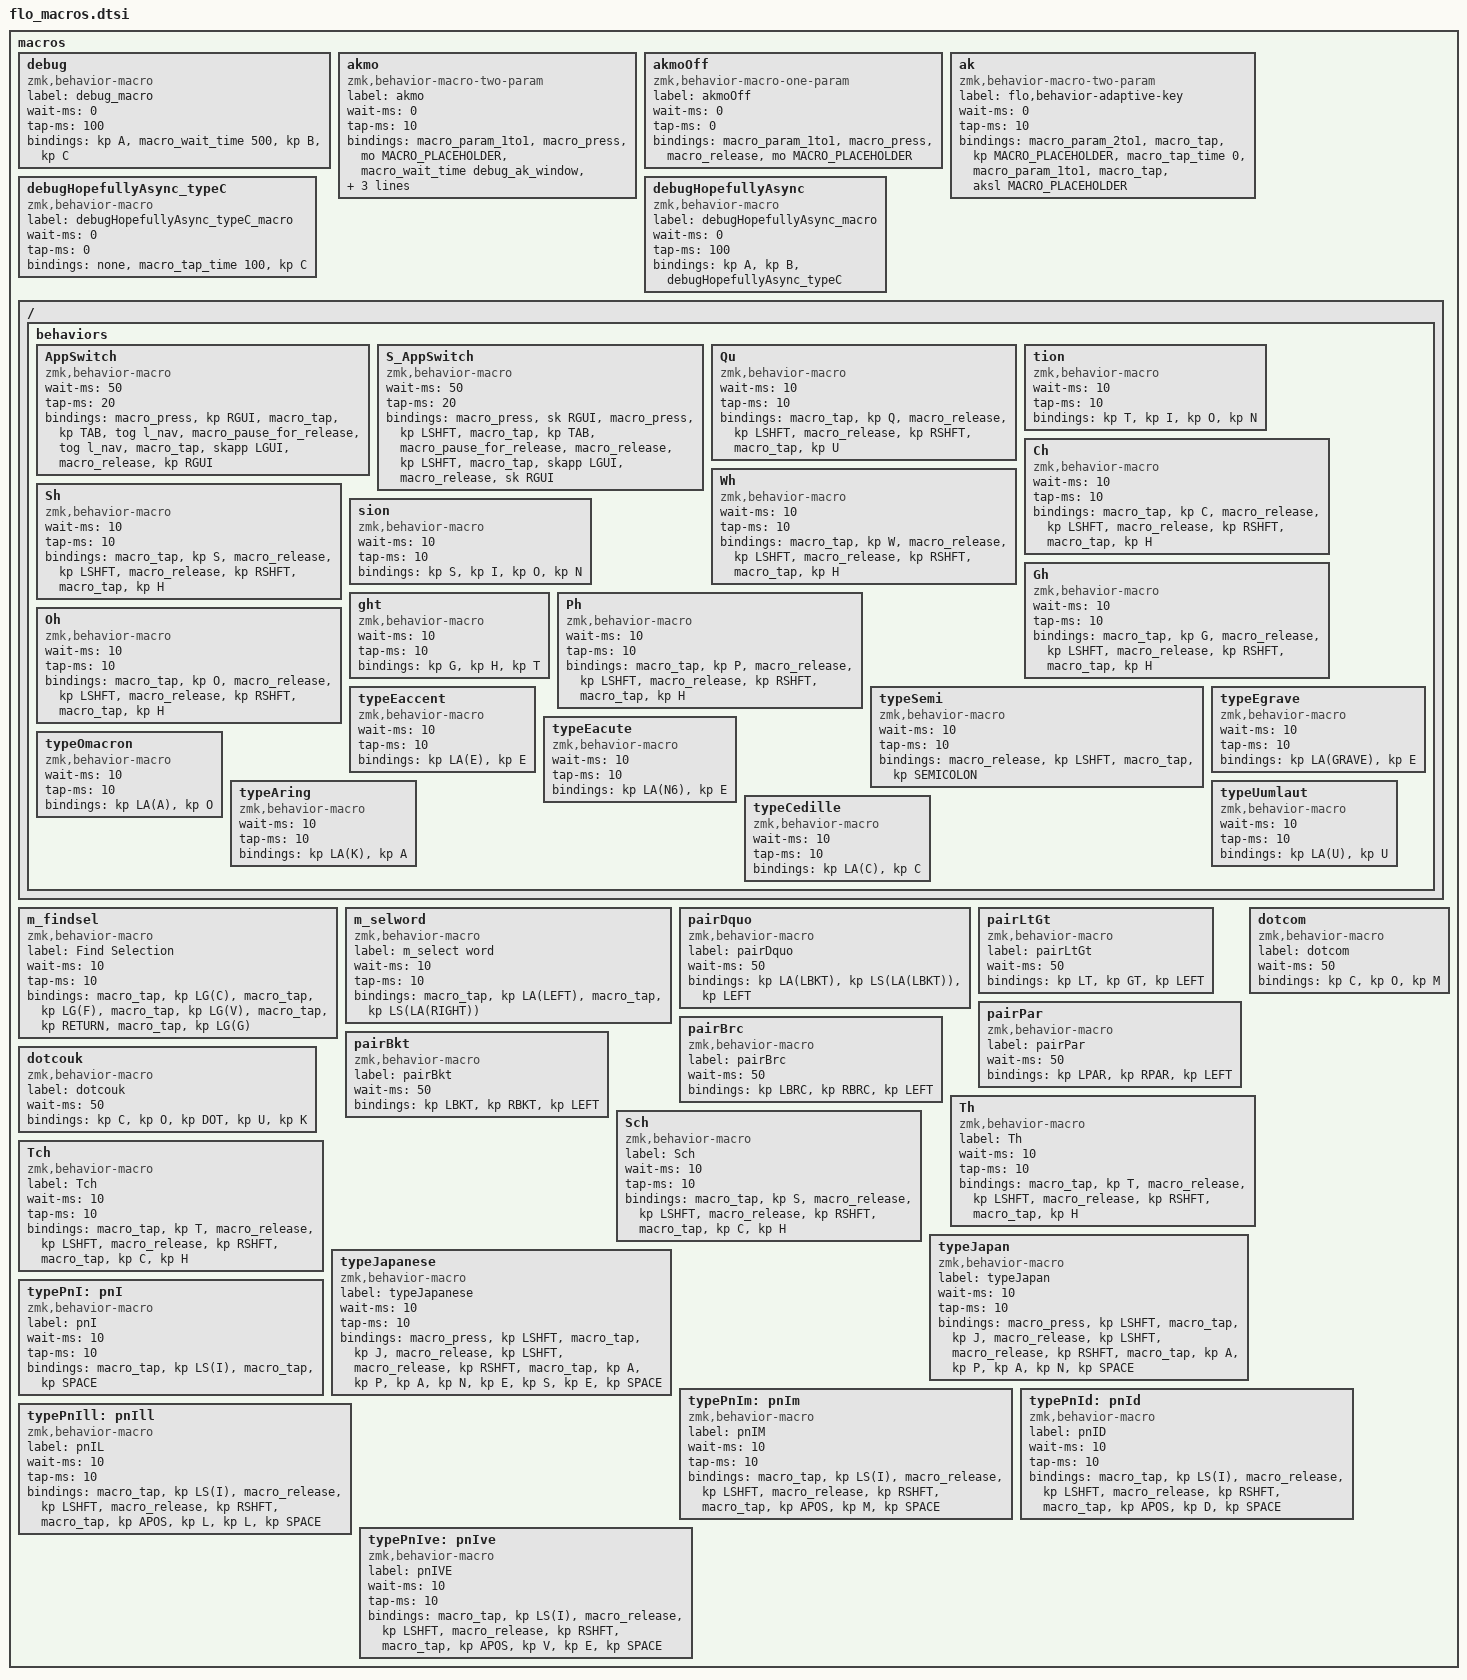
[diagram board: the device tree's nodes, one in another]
#define STRINGIFY(ARG) #ARG
#define REPLACE_CHAR_WITH_BIGRAM(BIGRAM_0, BIGRAM_1) \
        replace_char_with_bigram_##BIGRAM_0##BIGRAM_1: replace_char_with_bigram##BIGRAM_0##BIGRAM_1 { \
                label = STRINGIFY(flo-macro-replace-char-with-bigram-##BIGRAM_0##BIGRAM_1); \
                compatible = "zmk,behavior-macro"; \
                #binding-cells = <0>; \
                wait-ms = <0>; \
                tap-ms = <10>; \
                bindings = \
                        <&kp BACKSPACE>, \
\
                        <&kp BIGRAM_0>, \
\
                        <ak_##BIGRAM_1>; \
        };

macros {

        // Replace w/ Bigram for Vv only
        REPLACE_CHAR_WITH_BIGRAM(O, B)
        REPLACE_CHAR_WITH_BIGRAM(U, B)
        REPLACE_CHAR_WITH_BIGRAM(L, M)

        // Replace w/ Bigram for Vb
        REPLACE_CHAR_WITH_BIGRAM(S, B)
        REPLACE_CHAR_WITH_BIGRAM(I, F)
        REPLACE_CHAR_WITH_BIGRAM(L, G)
        REPLACE_CHAR_WITH_BIGRAM(B, J)
        REPLACE_CHAR_WITH_BIGRAM(D, J)
        REPLACE_CHAR_WITH_BIGRAM(N, J)
        REPLACE_CHAR_WITH_BIGRAM(L, K)
        REPLACE_CHAR_WITH_BIGRAM(N, K)
        REPLACE_CHAR_WITH_BIGRAM(B, M)
        REPLACE_CHAR_WITH_BIGRAM(L, N)
        REPLACE_CHAR_WITH_BIGRAM(N, M)
        REPLACE_CHAR_WITH_BIGRAM(P, M)

        debug: debug {
                label = "debug_macro";
                compatible = "zmk,behavior-macro";
                #binding-cells = <0>;
                wait-ms = <0>;
                tap-ms = <100>;
                bindings = 
                        <&kp A>,
                        <&macro_wait_time 500>,
                        <&kp B>,
                        <&kp C>;
        };

        // TODO: TRy with wait times, I think that's how I got it to work earlier. 
        // If can't figure out, reproduce the setup with 1000, 2000, 3000, 4000 delays to try and undersatnd again how it works.
        // YEEEEEEEEEEES THIS SEEMS TO WORK!!!! (somewhat, need to investigate more tomorrow 😌)
        // mmmm maybe not actually. Need to double check with 1000, 2000, etc..
#define debug_ak_window (my_ak_window / 2) // This is because the ak_window is doubled in the macro. I may be able to fix this later.
        akmo: akmo {
                label = "akmo";
                compatible = "zmk,behavior-macro-two-param";
                #binding-cells = <2>;
                wait-ms = <0>;
                tap-ms = <10>; // Was 0, but trying 10ms since I add a &kp in the mix
                bindings = 
                        <&macro_param_1to1>,
                        <&macro_press &mo MACRO_PLACEHOLDER>,

                        <&macro_wait_time debug_ak_window>,
                        <&macro_param_2to1>,
                        // <&macro_tap &kp MACRO_PLACEHOLDER>, // This one will pause 'ak_window' after invoked (before invoking &akmoOff)
                        <&macro_press &bk MACRO_PLACEHOLDER>, // This one will pause 'ak_window' after invoked (before invoking &akmoOff)

                        <&macro_param_1to1>,
                        <&macro_press &akmoOff MACRO_PLACEHOLDER>;
        };
        akmoOff: akmoOff {
                label = "akmoOff";
                compatible = "zmk,behavior-macro-one-param";
                #binding-cells = <1>;
                wait-ms = <0>; // Wait will only delay the _next_ action, but this macro only has one action, so it's useless here (and it would delay the 1st action of the next macro => Confusing!)
                tap-ms = <0>; // Tap is not used when just realeasing (&macro_release)
                bindings = 
                        <&macro_param_1to1>,
                        <&macro_press &macro_release &mo MACRO_PLACEHOLDER>;
        };

        ak: ak {
                label = "flo,behavior-adaptive-key";
                compatible = "zmk,behavior-macro-two-param";
                #binding-cells = <2>;
                wait-ms = <0>;
                tap-ms = <10>;
                bindings =
                        <&macro_param_2to1>,
                        <&macro_tap &kp MACRO_PLACEHOLDER>,

                        <&macro_tap_time 0>,

                        <&macro_param_1to1>,
                        <&macro_tap &aksl MACRO_PLACEHOLDER>;
        };


/*

THIS is the version from the drawings on reMarkable!

        akmo: akmo {
                label = "akmo";
                compatible = "zmk,behavior-macro";
                #binding-cells = <0>;
                wait-ms = <1000>;
                tap-ms = <0>; // Unused because we are just pressing (&macro_press, &akmoOff)
                bindings = 
                        <&macro_press &mo 10>,
                        <&akmoOff>;
        };
        akmoOff: akmoOff {
                label = "akmoOff";
                compatible = "zmk,behavior-macro";
                #binding-cells = <0>;
                wait-ms = <0>; // Wait will only delay the _next_ action, but this macro only has one action, so it's useless here (and it would delay the 1st action of the next macro => Confusing!)
                tap-ms = <0>; // Tap is not used when just realeasing (&macro_release)
                bindings = 
                        <&macro_release &mo 10>;
        };

*/






        debugHopefullyAsync_typeC: debugHopefullyAsync_typeC {
                label = "debugHopefullyAsync_typeC_macro";
                compatible = "zmk,behavior-macro";
                #binding-cells = <0>;
                wait-ms = <0>;
                tap-ms = <0>;
                bindings = 
                <&none>,
                <&macro_tap_time 100>,
                <&kp C>;
        };
        debugHopefullyAsync: debugHopefullyAsync {
                label = "debugHopefullyAsync_macro";
                compatible = "zmk,behavior-macro";
                #binding-cells = <0>;
                wait-ms = <0>;
                tap-ms = <100>;
                bindings = 
                        <&kp A>,
                        <&kp B>,
                        <&debugHopefullyAsync_typeC>;
        };


        ZMK_MACRO(AppSwitch,
                wait-ms = <50>;
                tap-ms = <20>;
                bindings =
                        <&macro_press &kp RGUI>    // leave GUI down to keep menu up
                        , <&macro_tap &kp TAB>       // (use press for repeat)
                        , <&tog l_nav>               // to navigate the app menu
                        , <&macro_pause_for_release> // hold to keep menu up or for repeat ...
                        , <&tog l_nav>               // done navigating
                        , <&macro_tap &skapp LGUI>   // release other GUI after a timeout
                        , <&macro_release &kp RGUI>  // release the previous hold
                        ;
        )
        ZMK_MACRO(S_AppSwitch,
                wait-ms = <50>;
                tap-ms = <20>;
                bindings =
                        <&macro_press &sk RGUI> // leave GUI down to keep menu up
                        , <&macro_press &kp LSHFT> //
                        , <&macro_tap &kp TAB> // just tap for no repeat
                        , <&macro_pause_for_release> // hold for repeat ...
                        , <&macro_release &kp LSHFT> //
                        , <&macro_tap &skapp LGUI> // release other GUI after a timeout
                        , <&macro_release &sk RGUI> // now release the previous hold
                        ;
        )



        m_findsel: m_findsel {
                label = "Find Selection";
                compatible = "zmk,behavior-macro";
                #binding-cells = <0>;
                wait-ms = <10>;
                tap-ms = <10>;
                bindings = <&macro_tap &kp LG(C)>
                        , <&macro_tap &kp LG(F)>
                        , <&macro_tap &kp LG(V)>
                        , <&macro_tap &kp RETURN>
                        , <&macro_tap &kp LG(G)>;
        };

        m_selword: m_selword {
                label = "m_select word";
                compatible = "zmk,behavior-macro";
                #binding-cells = <0>;
                wait-ms = <10>;
                tap-ms = <10>;
                bindings = <&macro_tap &kp LA(LEFT)>
                        , <&macro_tap &kp LS(LA(RIGHT))>;
        };


        ZMK_MACRO(Qu,
                wait-ms = <10>;
                tap-ms = <10>;
                bindings = <&macro_tap &kp Q>
                        , <&macro_release &kp LSHFT>
                        , <&macro_release &kp RSHFT>
                        , <&macro_tap &kp U>
                        ;
        )

        pairDquo: pairDquo {
                label = "pairDquo";
                compatible = "zmk,behavior-macro";
                #binding-cells = <0>;
                wait-ms = <50>; // need to slow this down for some systems.
                bindings = <&kp LA(LBKT) &kp LS(LA(LBKT)) &kp LEFT>;
        };
        pairLtGt: pairLtGt {
                label = "pairLtGt";
                compatible = "zmk,behavior-macro";
                #binding-cells = <0>;
                wait-ms = <50>; // need to slow this down for some systems.
                bindings = <&kp LT &kp GT &kp LEFT>;
        };
        pairPar: pairPar {
                label = "pairPar";
                compatible = "zmk,behavior-macro";
                #binding-cells = <0>;
                wait-ms = <50>; // need to slow this down for some systems.
                bindings = <&kp LPAR &kp RPAR &kp LEFT>;
        };
        pairBrc: pairBrc {
                label = "pairBrc";
                compatible = "zmk,behavior-macro";
                #binding-cells = <0>;
                wait-ms = <50>; // need to slow this down for some systems.
                bindings = <&kp LBRC &kp RBRC &kp LEFT>;
        };
        pairBkt: pairBkt {
                label = "pairBkt";
                compatible = "zmk,behavior-macro";
                #binding-cells = <0>;
                wait-ms = <50>; // need to slow this down for some systems.
                bindings = <&kp LBKT &kp RBKT &kp LEFT>;
        };

        dotcom: dotcom {
                label = "dotcom";
                compatible = "zmk,behavior-macro";
                #binding-cells = <0>;
                wait-ms = <50>; // need to slow this down for some systems.
                bindings = <&kp C &kp O &kp M> ;
        };
        dotcouk: dotcouk {
                label = "dotcouk";
                compatible = "zmk,behavior-macro";
                #binding-cells = <0>;
                wait-ms = <50>; // need to slow this down for some systems.
                bindings = <&kp C &kp O &kp DOT &kp U &kp K>;
        };


// TODO: Rework all digraphs with a 2 param macro
        Th: Th {
                label = "Th";
                compatible = "zmk,behavior-macro";
                #binding-cells = <0>;
                wait-ms = <10>;
                tap-ms = <10>;
                bindings = <&macro_tap &kp T>
                , <&macro_release &kp LSHFT>
                , <&macro_release &kp RSHFT>
                , <&macro_tap &kp H>;
        };
        ZMK_MACRO(tion,
                wait-ms = <10>;
                tap-ms = <10>;
                bindings = <&kp T &kp I &kp O &kp N>;
        )
        ZMK_MACRO(Ch,
                wait-ms = <10>;
                tap-ms = <10>;
                bindings = <&macro_tap &kp C>
                        , <&macro_release &kp LSHFT>
                        , <&macro_release &kp RSHFT>
                        , <&macro_tap &kp H>;
        )
        ZMK_MACRO(Wh,
                wait-ms = <10>;
                tap-ms = <10>;
                bindings = <&macro_tap &kp W>
                        , <&macro_release &kp LSHFT>
                        , <&macro_release &kp RSHFT>
                        , <&macro_tap &kp H>;
        )
        ZMK_MACRO(Sh,
                wait-ms = <10>;
                tap-ms = <10>;
                bindings = <&macro_tap &kp S>
                        , <&macro_release &kp LSHFT>
                        , <&macro_release &kp RSHFT>
                        , <&macro_tap &kp H>
                        ;
                )
        ZMK_MACRO(sion,
                wait-ms = <10>;
                tap-ms = <10>;
                bindings = <&kp S &kp I &kp O &kp N>
                        ;
                )
        ZMK_MACRO(Gh,
                wait-ms = <10>;
                tap-ms = <10>;
                bindings = <&macro_tap &kp G>
                        , <&macro_release &kp LSHFT>
                        , <&macro_release &kp RSHFT>
                        , <&macro_tap &kp H>
                        ;
                )
        ZMK_MACRO(ght,
                wait-ms = <10>;
                tap-ms = <10>;
                bindings = <&kp G &kp H &kp T>
                        ;
                )
        ZMK_MACRO(Ph,
                wait-ms = <10>;
                tap-ms = <10>;
                bindings = <&macro_tap &kp P>
                        , <&macro_release &kp LSHFT>
                        , <&macro_release &kp RSHFT>
                        , <&macro_tap &kp H>
                        ;
                )
        ZMK_MACRO(Oh,
                wait-ms = <10>;
                tap-ms = <10>;
                bindings = <&macro_tap &kp O>
                        , <&macro_release &kp LSHFT>
                        , <&macro_release &kp RSHFT>
                        , <&macro_tap &kp H>
                        ;
                )


        Sch: Sch {
                label = "Sch";
                compatible = "zmk,behavior-macro";
                #binding-cells = <0>;
                wait-ms = <10>;
                tap-ms = <10>;
                bindings = <&macro_tap &kp S>
                        , <&macro_release &kp LSHFT>
                        , <&macro_release &kp RSHFT>
                        , <&macro_tap &kp C &kp H>
                        ;
        };
        Tch: Tch {
                label = "Tch";
                compatible = "zmk,behavior-macro";
                #binding-cells = <0>;
                wait-ms = <10>;
                tap-ms = <10>;
                bindings = <&macro_tap &kp T>
                        , <&macro_release &kp LSHFT>
                        , <&macro_release &kp RSHFT>
                        , <&macro_tap &kp C &kp H>
                        ;
        };

        ZMK_MACRO(typeSemi,
                wait-ms = <10>;
                tap-ms = <10>;
                bindings = <&macro_release &kp LSHFT>
                        , <&macro_tap &kp SEMICOLON>
                        ;
        )
        ZMK_MACRO(typeEaccent,
                wait-ms = <10>;
                tap-ms = <10>;
                bindings = <&kp LA(E) &kp E>
                        ;
        )
        ZMK_MACRO(typeEgrave,
                wait-ms = <10>;
                tap-ms = <10>;
                bindings = <&kp LA(GRAVE) &kp E>
                        ;
        )
        ZMK_MACRO(typeEacute,
                wait-ms = <10>;
                tap-ms = <10>;
                bindings = <&kp LA(N6) &kp E>
                        ;
        )
        ZMK_MACRO(typeOmacron,
                wait-ms = <10>;
                tap-ms = <10>;
                bindings = <&kp LA(A) &kp O>
                        ;
        )
        ZMK_MACRO(typeAring,
                wait-ms = <10>;
                tap-ms = <10>;
                bindings = <&kp LA(K) &kp A>
                        ;
        )
        ZMK_MACRO(typeUumlaut,
                wait-ms = <10>;
                tap-ms = <10>;
                bindings = <&kp LA(U) &kp U>
                        ;
        )
        ZMK_MACRO(typeCedille,
                wait-ms = <10>;
                tap-ms = <10>;
                bindings = <&kp LA(C) &kp C>
                        ;
        )
        typeJapan: typeJapan {
                label = "typeJapan";
                compatible = "zmk,behavior-macro";
                #binding-cells = <0>;
                wait-ms = <10>;
                tap-ms = <10>;
                bindings = <&macro_press &kp LSHFT>
                        , <&macro_tap &kp J>
                        , <&macro_release &kp LSHFT>
                        , <&macro_release &kp RSHFT>
                        , <&macro_tap &kp A &kp P &kp A &kp N &kp SPACE>
                        ;
        };
        typeJapanese: typeJapanese {
                label = "typeJapanese";
                compatible = "zmk,behavior-macro";
                #binding-cells = <0>;
                wait-ms = <10>;
                tap-ms = <10>;
                bindings = <&macro_press &kp LSHFT>
                        , <&macro_tap &kp J>
                        , <&macro_release &kp LSHFT>
                        , <&macro_release &kp RSHFT>
                        , <&macro_tap &kp A &kp P &kp A &kp N &kp E &kp S &kp E &kp SPACE>
                        ;
        };





        // I
        typePnI: pnI {
                label = "pnI";
                compatible = "zmk,behavior-macro";
                #binding-cells = <0>;
                wait-ms = <10>;
                tap-ms = <10>;
                bindings = <&macro_tap &kp LS(I)>
                        , <&macro_tap &kp SPACE>
                        ;
        };
        typePnIm: pnIm {
                label = "pnIM";
                compatible = "zmk,behavior-macro";
                #binding-cells = <0>;
                wait-ms = <10>;
                tap-ms = <10>;
                bindings = <&macro_tap &kp LS(I)>
                        , <&macro_release &kp LSHFT>
                        , <&macro_release &kp RSHFT>
                        , <&macro_tap &kp APOS &kp M &kp SPACE>
                        ;
        };
        typePnId: pnId {
                label = "pnID";
                compatible = "zmk,behavior-macro";
                #binding-cells = <0>;
                wait-ms = <10>;
                tap-ms = <10>;
                bindings = <&macro_tap &kp LS(I)>
                        , <&macro_release &kp LSHFT>
                        , <&macro_release &kp RSHFT>
                        , <&macro_tap &kp APOS &kp D &kp SPACE>
                        ;
        };
        typePnIll: pnIll {
                label = "pnIL";
                compatible = "zmk,behavior-macro";
                #binding-cells = <0>;
                wait-ms = <10>;
                tap-ms = <10>;
                bindings = <&macro_tap &kp LS(I)>
                        , <&macro_release &kp LSHFT>
                        , <&macro_release &kp RSHFT>
                        , <&macro_tap &kp APOS &kp L &kp L &kp SPACE>
                        ;
        };
        typePnIve: pnIve {
                label = "pnIVE";
                compatible = "zmk,behavior-macro";
                #binding-cells = <0>;
                wait-ms = <10>;
                tap-ms = <10>;
                bindings = <&macro_tap &kp LS(I)>
                        , <&macro_release &kp LSHFT>
                        , <&macro_release &kp RSHFT>
                        , <&macro_tap &kp APOS &kp V &kp E &kp SPACE>
                        ;
        };

        // // YOU
        // typePnYoure: pnYoure {
        //         label = "pnYoure";
        //         compatible = "zmk,behavior-macro";
        //         #binding-cells = <0>;
        //         wait-ms = <10>;
        //         tap-ms = <10>;
        //         bindings = <&macro_tap &kp Y>
        //                 , <&macro_release &kp LSHFT>
        //                 , <&macro_release &kp RSHFT>
        //                 , <&macro_tap &kp O &kp U &kp APOS &kp R &kp E &kp SPACE>
        //                 ;
        // };
        // typePnYoud: pnYoud {
        //         label = "pnYou'd";
        //         compatible = "zmk,behavior-macro";
        //         #binding-cells = <0>;
        //         wait-ms = <10>;
        //         tap-ms = <10>;
        //         bindings = <&macro_tap &kp Y>
        //                 , <&macro_release &kp LSHFT>
        //                 , <&macro_release &kp RSHFT>
        //                 , <&macro_tap &kp O &kp U &kp APOS &kp D &kp SPACE>
        //                 ;
        // };
        // typePnYoull: pnYoull {
        //         label = "pnYou'll";
        //         compatible = "zmk,behavior-macro";
        //         #binding-cells = <0>;
        //         wait-ms = <10>;
        //         tap-ms = <10>;
        //         bindings = <&macro_tap &kp Y>
        //                 , <&macro_release &kp LSHFT>
        //                 , <&macro_release &kp RSHFT>
        //                 , <&macro_tap &kp O &kp U &kp APOS &kp L &kp L &kp SPACE>
        //                 ;
        //         };
        // typePnYouve: pnYouve {
        // label = "pnYou've";
        //         compatible = "zmk,behavior-macro";
        //         #binding-cells = <0>;
        //         wait-ms = <10>;
        //         tap-ms = <10>;
        //         bindings = <&macro_tap &kp Y>
        //                 , <&macro_release &kp LSHFT>
        //                 , <&macro_release &kp RSHFT>
        //                 , <&macro_tap &kp O &kp U &kp APOS &kp V &kp E &kp SPACE>
        //                 ;
        //         };

        // // WE
        // typePnWere: pnWere {
        //         label = "pnWere";
        //         compatible = "zmk,behavior-macro";
        //         #binding-cells = <0>;
        //         wait-ms = <10>;
        //         tap-ms = <10>;
        //         bindings = <&macro_tap &kp W>
        //                 , <&macro_release &kp LSHFT>
        //                 , <&macro_release &kp RSHFT>
        //                 , <&macro_tap &kp E &kp APOS &kp R &kp E &kp SPACE>
        //                 ;
        // };
        // typePnWed: pnWed {
        //         label = "pnWe'd";
        //         compatible = "zmk,behavior-macro";
        //         #binding-cells = <0>;
        //         wait-ms = <10>;
        //         tap-ms = <10>;
        //         bindings = <&macro_tap &kp W>
        //                 , <&macro_release &kp LSHFT>
        //                 , <&macro_release &kp RSHFT>
        //                 , <&macro_tap &kp E &kp APOS &kp D &kp SPACE>
        //                 ;
        // };
        // typePnWell: pnWell {
        //         label = "pnWe'll";
        //         compatible = "zmk,behavior-macro";
        //         #binding-cells = <0>;
        //         wait-ms = <10>;
        //         tap-ms = <10>;
        //         bindings = <&macro_tap &kp W>
        //                 , <&macro_release &kp LSHFT>
        //                 , <&macro_release &kp RSHFT>
        //                 , <&macro_tap &kp E &kp APOS &kp L &kp L &kp SPACE>
        //                 ;
        // };
        // typePnWeve: pnWeve {
        //         label = "pnWe've";
        //         compatible = "zmk,behavior-macro";
        //         #binding-cells = <0>;
        //         wait-ms = <10>;
        //         tap-ms = <10>;
        //         bindings = <&macro_tap &kp W>
        //                 , <&macro_release &kp LSHFT>
        //                 , <&macro_release &kp RSHFT>
        //                 , <&macro_tap &kp E &kp APOS &kp V &kp E &kp SPACE>
        //                 ;
        // };

};
